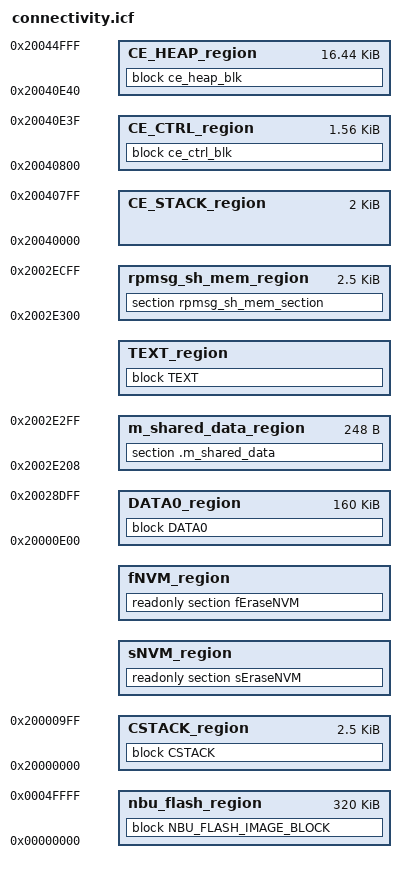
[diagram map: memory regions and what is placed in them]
/*
** ###################################################################
**     Processors:          MCXW70ACMFT
**                          MCXW70ACMMP
**
**     Compiler:            IAR ANSI C/C++ Compiler for ARM
**
**     Abstract:
**         Linker file for the IAR ANSI C/C++ Compiler for ARM for Connectivity Demo Applications
**
**     Copyright 2025-2026 NXP
**
**     SPDX-License-Identifier: BSD-3-Clause
**
**     http:                 www.nxp.com
**     mail:                 support@nxp.com
**
** ###################################################################
*/

/* Linker script for BLE or/and OpenThread applications
 * This is a generic layout with optional region that could be needed for BLE or OpenThread applications.
 * This Linker file can be used for BLE/OT combo applications. */

/*******************************************  core0/core1 common defines **********************************************/

/* flash */
define symbol m_flash_start = 0x0;
define symbol m_flash_size  = 0x180000;
define symbol m_flash_end   = m_flash_start + m_flash_size - 1;
define symbol m_sector_size = 0x2000;

/* FLW - the application flash region */
define symbol m_flw_start = 0x00800000;
define symbol m_flw_size  = 0x180000;
define symbol m_flw_end   = m_flw_start + m_flw_size - 1;

/* 320K reserved flash space for the Radio core at the beginning of the flash */
define symbol m_flash_radio_size    = 40 * m_sector_size;
define symbol m_flash_radio_start   = m_flash_start;
define symbol m_flash_radio_end     = m_flash_radio_start + m_flash_radio_size - 1;

/* RAM */
define symbol m_ram_size    = 0x10000; // all ram banks are 64K
define symbol m_ram0_start  = 0x20000000;
define symbol m_ram0_end    = m_ram0_start + m_ram_size -1;
define symbol m_ram1_start  = 0x20010000;
define symbol m_ram1_end    = m_ram1_start + m_ram_size - 1;
define symbol m_ram2_start  = 0x20020000;
define symbol m_ram2_end    = m_ram2_start + m_ram_size - 1;

/* ram3 is mapped to 0x04030000 as TCM-CODE but also remapped to 0x20030000 as TCM-SYSR (data)
 * For connectivity applications, this bank is reserved to the NBU core, core0 shall not use it */
define symbol m_ram3_start  = 0x20030000;
define symbol m_ram3_end    = m_ram3_start + m_ram_size - 1;

/* 8K shared ram between core0 and core1 - located at the end of the third ram bank */
define symbol m_shared_ram_size     = 0x2000;
define symbol m_shared_ram_end      = m_ram2_end;
define symbol m_shared_ram_start    = m_shared_ram_end - m_shared_ram_size + 1;

/* core0 and core1 RAM shared bank
 * core0 : 0x8E00 (35.5K)
 * core1 : 0x5200 (20.5K)
 * shared between both : 8k
*/
define symbol m_core1_shared_ram_end   = m_shared_ram_start - 1;
define symbol m_core1_shared_ram_size  = 0x5200;
define symbol m_core1_shared_ram_start = m_core1_shared_ram_end - m_core1_shared_ram_size + 1;

/* core0 reserved RAM (128K + 0x8E00 = 163.5K) */
define symbol m_core0_ram_start = m_ram0_start;
define symbol m_core0_ram_end   = m_core1_shared_ram_start - 1;

/* core1 reserved RAM (64k) */
define symbol m_core1_ram_start = m_ram3_start;
define symbol m_core1_ram_end   = m_ram3_end;

/* Shared memory placements
 * Do not change shall be aligned with nbu firmware image */

/* Section allowing to share debug info between core0 and core1 */
define exported symbol m_sqram_debug_start      = m_shared_ram_start;
define symbol m_sqram_debug_size                = 0x200;
define symbol m_sqram_debug_end                 = m_sqram_debug_start + m_sqram_debug_size - 1;

/* Section used to share platform/services (SFC, Lowpower) information */
define symbol framework_info_sh_mem_start       = m_sqram_debug_end + 1;
define symbol framework_info_sh_mem_size        = 0x100;
define symbol framework_info_sh_mem_end         = framework_info_sh_mem_start + framework_info_sh_mem_size - 1;
define exported symbol m_sfc_log_start          = framework_info_sh_mem_start;
define symbol m_sfc_log_size                    = 0x04;
define exported symbol m_lowpower_flag_start    = framework_info_sh_mem_start + m_sfc_log_size;
define symbol m_lowpower_flag_size              = 0x04;
define symbol m_lowpower_flag_end               = m_lowpower_flag_start + m_lowpower_flag_size - 1;
define symbol m_shared_data_start               = m_lowpower_flag_end + 1;
define symbol m_shared_data_size                = 0xF8;
define symbol m_shared_data_end                 = m_shared_data_start + m_shared_data_size - 1;
/* Make sure we don't overflow the framework_info_sh_mem */
check that m_shared_data_end <= framework_info_sh_mem_end;

define exported symbol rpmsg_sh_mem_start       = framework_info_sh_mem_end + 1;
define exported symbol rpmsg_sh_mem_size        = 0xA00;
define exported symbol rpmsg_sh_mem_end         = rpmsg_sh_mem_start + rpmsg_sh_mem_size - 1;

/* fill the remaining space with the logging buffer */
define exported symbol dbg_ext_logging_start    = rpmsg_sh_mem_end + 1;
define exported symbol dbg_ext_logging_size     = m_shared_ram_size - (dbg_ext_logging_start - m_shared_ram_start);
define exported symbol dbg_ext_logging_end      = dbg_ext_logging_start + dbg_ext_logging_size - 1;

/* Make sure we don't overflow the reserved shared memory region */
check that dbg_ext_logging_end <= m_shared_ram_end;

/*************************** FLASH LAYOUT ***********************************

                             0x001F_FFFF    m_flash_end
                    - - - +---------------+ - - - - - - - -
                          |               | m_fsl_prodInfo_end
                          |               |
                          | Product Info  | Enable with gUseProdInfoMainFlashMode_d=1
                          |               |
                          |               | m_fsl_prodInfo_start
                    - - - +---------------+ - - - - - - - -
                          |               | NV_STORAGE_END_ADDRESS
                          |  NV_STORAGE*  |
                          |               | Enable with gUseNVMLink_d=1
                          |               |
                          |               | NV_STORAGE_START_ADDRESS
                    - - - +---------------+ - - - - - - - -
                          |               | INT_STORAGE_END
                          |               |
                          |               |
                          |               |
                          | OTAP Internal | Enable with gUseInternalStorageLink_d=1
                          |      Storage* |
                          |               |
                          |               |
                          |               |
                          |               | INT_STORAGE_START
                    - - - +---------------+ - - - - - - - -
                          |               | m_text_end
                          |               |
                          |               |
                          |               |
                          | Application** |
                          |               |
                          |               |
                          |               |
                          |               | m_text_start
                    - - - +---------------+ - - - - - - - -
                          |   Interrupt   | m_interrupts_end
                          |    Vectors    |
                          |               | m_interrupts_start
                    - - - +---------------+ - - - - - - - -
                             0x0000_0000

        * - These sections are optional for certain applications
       ** - Application will occupy all the free space available
*****************************************************************************/

/* Symbols Flash checks */

if (!isdefinedsymbol(gUseNVMLink_d)) {
    define symbol gUseNVMLink_d = 0;
}

if (!isdefinedsymbol(gEraseNVMLink_d)) {
    define symbol gEraseNVMLink_d = 0;
}

if (!isdefinedsymbol(gUseInternalStorageLink_d)) {
    define symbol gUseInternalStorageLink_d = 0;
}

if (!isdefinedsymbol(gFlashNbuImage_d)) {
    define symbol gFlashNbuImage_d = 0;
}

/* By default, gFlashNbuLogging_d is not used. */
if (!isdefinedsymbol(gFlashNbuLogging_d)) {
    define symbol gFlashNbuLogging_d = 0;
}

if (!isdefinedsymbol(gUseProdInfoMainFlashMode_d)) {
    define symbol gUseProdInfoMainFlashMode_d = 0;
}

/* Symbols RAM checks */

/* Give SRAM room for ROM code to support warm boot from powerdown mode if this feature is supported and enabled */
if (!isdefinedsymbol(gLowpowerPowerDownEnable_d)) {
    define exported symbol gLowpowerPowerDownEnable_d = 0;
}
else {
    export symbol gLowpowerPowerDownEnable_d;
}

if (!isdefinedsymbol(gReserveCeRam_d)) {
    define exported symbol gReserveCeRam_d = 0;
}

/********************************************** FLASH **********************************************/

/* Flash defines */
define symbol m_vector_table_size                       = 0x400;   /* define is used for warmboot stack size too */

/* NVM and INT_STORAGE will use the physical flash address and not the FLW range
 * This adds some complexity because we have to translate between physical address and FLW address
 */

/* NVM storage */
if ( gUseNVMLink_d ) {
    if (isdefinedsymbol(gNVMSectorCountLink_d)) {
        define exported symbol NV_STORAGE_MAX_SECTORS   = gNVMSectorCountLink_d;
    }
    else {
        define exported symbol NV_STORAGE_MAX_SECTORS   = 4;
    }
}
else {
    define exported symbol NV_STORAGE_MAX_SECTORS       = 0;
}
define exported symbol NV_STORAGE_SECTOR_SIZE           = m_sector_size;
define exported symbol NV_STORAGE_END_ADDRESS           = m_flash_end; /* MUST use physical flash address and not FLW */
define exported symbol NV_STORAGE_SIZE                  = (NV_STORAGE_MAX_SECTORS * NV_STORAGE_SECTOR_SIZE);
define exported symbol NV_STORAGE_START_ADDRESS         = NV_STORAGE_END_ADDRESS - NV_STORAGE_SIZE + 1;

/* OTA */
define exported symbol INT_STORAGE_END                  = NV_STORAGE_START_ADDRESS - 1;
if (gUseInternalStorageLink_d) {
    /* The NBU firmware is located at the start of the flash so we have to compute the physical start address of the
     * application, meaning m_flash_start + m_flash_radio_size
     */
    define symbol m_app_flash_start                     = m_flash_start + m_flash_radio_size;
    define exported symbol INT_STORAGE_SIZE             = m_sector_size * ( ((INT_STORAGE_END + 1 - (m_app_flash_start))/2)/m_sector_size +1);
}
else {
    define exported symbol INT_STORAGE_SIZE             = 0;
}
define exported symbol INT_STORAGE_START                = INT_STORAGE_END - INT_STORAGE_SIZE + 1;
define exported symbol INT_STORAGE_SECTOR_SIZE          = m_sector_size;

/* This m_image_length is used to define the image length field in the vector table for boot ROM - it is mandatory.
 * We set it to the total available space for the application code minus the reserved areas.
 * We could simplify and use the whole FLW space but we wouldn't be able to detect if the application overflows
 * in the reserved areas since they are referring to the physical flash address instead of FLW.
 * This way, we are able to limit the size of the application code to the available space.
 */
define symbol m_reserved_size           = NV_STORAGE_END_ADDRESS - INT_STORAGE_START + 1;
define exported symbol m_image_length   = m_flw_size - m_flash_radio_size - m_reserved_size;

/* code is placed within FLW range */
define exported symbol m_text_start                     = m_flw_start;
define exported symbol m_text_end                       = m_flw_start + m_image_length - 1;
define exported symbol __VECTOR_TABLE                   = m_text_start;

/*************************** RAM LAYOUT ************************************/

/*
Default address values are indicated between brackets they can be overridden if necessary by linker flags


                    - - - +---------------+ - - - - - - - -
            (0x20044FFF)  |               | m_ce_heap_end
                          |               |
                          |               | Enable with gReserveCeRam_d=1
                          |               |
            (0x20040E40)  |               | m_ce_heap_start
                    - - - +---------------+ - - - - - - - -
            (0x20040E3F)  |               | m_ce_ctrl_end
                          |               |
                          |               | Enable with gReserveCeRam_d=1
                          |               |
            (0x20040800)  |               | m_ce_ctrl_start
                    - - - +---------------+ - - - - - - - -
            (0x200407FF)  |               | m_ce_stack_end
                          |               |
                          |               | Enable with gReserveCeRam_d=1
                          |               |
            (0x20040000)  |               | m_ce_stack_start
                   - - - +---------------+ - - - - - - - -
            (0x2003FFFF)  |               | m_core1_ram_end
                          |               |
                          |               |
            (0x20030000)  |               | m_core1_ram_start
                    - - - +---------------+ - - - - - - - -
            (0x2002FFFF)  |               | m_shared_ram_end
                          |               |
                          |               |
            (0x2002E000)  |               | m_shared_ram_start
                    - - - +---------------+ - - - - - - - -
            (0x2002DFFF)  |               | m_core1_shared_ram_end
                          |               |
                          |               |
            (0x20028E00)  |               | m_core1_shared_ram_start
                    - - - +---------------+ - - - - - - - -
              0x20028DFF  |     HEAP      | m_core0_ram_end \ m_data0_end \ __HEAP_end__
                          |               |
                          |               |
                          |...............| __HEAP_start__
                          |               |
                          .     Data0     .
                          .               .

            (0x20000E00)  |               | m_data0_start
                    - - - +---------------+ - - - - - - - -
                          |               | m_interrupts_ram_end
                          | vector table  |
            (0x20000A00)  |               | m_interrupts_ram_start
                    - - - +---------------+ - - - - - - - -
                          |               | m_cstack_end
                          |    Reserved   |
                          |               | m_cstack_start
                    - - - +---------------+ - - - - - - - -
              0x20000000  |               | m_core0_ram_start

**************************************************************************************************/

/********************************************** RAM **********************************************/

if (!isdefinedsymbol(__stack_size__))
{
    define symbol __stack_size__    = 0x0A00;
}

if (!isdefinedsymbol(__heap_size__))
{
    define symbol __heap_size__     = 0x0A00;
}

/* On A0 revisions of this chip, the CPU boot ROM does NOT correctly start the
 * application if the initial Main Stack Pointer (MSP) is located in SRAM1.
 * When the application’s SP is placed in SRAM1, the boot ROM refuses to jump
 * to the application entry point, resulting in a silent boot failure.
 *
 * Do NOT relocate the cstack region on A0 silicon.
 */
define exported symbol m_cstack_start                   = m_core0_ram_start;
define exported symbol m_cstack_end                     = m_cstack_start + __stack_size__ - 1;

/* Ram vector table */
define symbol m_interrupts_ram_start                    = m_cstack_end + 1;
define symbol m_ram_vector_table_size                   = m_vector_table_size;
define symbol m_interrupts_ram_end                      = m_interrupts_ram_start + m_ram_vector_table_size - 1;
define exported symbol __VECTOR_RAM                     = m_interrupts_ram_start;
define exported symbol __RAM_VECTOR_TABLE_SIZE          = m_ram_vector_table_size;

/* data0 region */
define symbol m_data0_start = m_interrupts_ram_end + 1;
define symbol m_data0_end   = m_core0_ram_end;

/* Data region Size for Compute Engine (CE) */
if (gReserveCeRam_d)
{
    define symbol m_ce_data_size                        = 0x1A000;
}
else
{
    define symbol m_ce_data_size                        = 0x0;
}

/* Heap region start and end address symbols used by usual memory allocator (malloc(), free())
   Not used by fsl_component_memory_manager_light component, __heap_size__ can be NULL */
define exported symbol __HEAP_start__                   = m_data0_end - __heap_size__;
define exported symbol __HEAP_end__                     = m_data0_end;

/* TODO: currently covering all the RAM to be safe */
define exported symbol firmware_ram_upper_limit         = m_core0_ram_end;
define exported symbol firmware_ram_lower_limit         = m_core0_ram_start;

/* Zephyr coredump LINKER_RAM region (DEBUG_COREDUMP_MEMORY_DUMP_LINKER_RAM,
 * the whole-RAM dump method). coredump_memory_regions.c brackets the RAM
 * portion of the dump between _image_ram_start and _image_ram_end. The Zephyr
 * build normally emits these; on the connectivity linker they are defined here
 * over the whole core0 RAM bank so the entire application RAM is dumped. */
define exported symbol _image_ram_start                 = m_core0_ram_start;
define exported symbol _image_ram_end                   = m_core0_ram_end;

/* The layout of the RAM and the region of each section have been reorganized in order
 * to optimize the RAM banks in retention. The heap at the top, we do not need to retain
 * banks upper of the last address used by the heap. */

/********************************************** Regions **********************************************/

/* shared memory regions */
define region rpmsg_sh_mem_region       = mem:[from rpmsg_sh_mem_start to rpmsg_sh_mem_end];
define region m_shared_data_region      = mem:[from m_shared_data_start to m_shared_data_end];

/* core0 memory regions */
define region TEXT_region               = mem:[from m_text_start to m_text_end];
define region DATA0_region              = mem:[from m_data0_start to m_data0_end];
define region CSTACK_region             = mem:[from m_cstack_start to m_cstack_end];

/* define blocks */
define block TEXT {
    first readonly section .intvec,
    readonly
};

/* Use DATA1_region for all connectivity code - DATA0_Region is 32K, can be used for customer specific code */
define block DATA0                                                  { readwrite, zi, last section .heap };
define block CSTACK    with alignment = 8, size = __stack_size__    { };

initialize by copy { readwrite, section .textrw };

if (isdefinedsymbol(__USE_DLIB_PERTHREAD))
{
  /* Required in a multi-threaded application */
  initialize by copy with packing = none { section __DLIB_PERTHREAD };
}

do not initialize  { section .noinit };
do not initialize  { section .heap };
do not initialize  { section .rpmsg_sh_mem_section};

/********************************************** PLACEMENT **********************************************/

/* shared memory placements */
place in rpmsg_sh_mem_region                    { section rpmsg_sh_mem_section };
place in m_shared_data_region                   { section .m_shared_data };

/* core0 memory placements */
place in TEXT_region                            { block TEXT };
place in DATA0_region                           { block DATA0 };
place in CSTACK_region                          { block CSTACK };

if (gUseNVMLink_d) {
    define symbol NV_VIRTUAL_PAGE_BOUND = NV_STORAGE_END_ADDRESS - (NV_STORAGE_MAX_SECTORS/2 * NV_STORAGE_SECTOR_SIZE);
    define region sNVM_region           = mem:[from  NV_VIRTUAL_PAGE_BOUND+1 to NV_STORAGE_END_ADDRESS];
    define region fNVM_region           = mem:[from  NV_STORAGE_START_ADDRESS to NV_VIRTUAL_PAGE_BOUND];
    if(gEraseNVMLink_d)
    {
        place in fNVM_region              {readonly section fEraseNVM };
        place in sNVM_region              {readonly section sEraseNVM };
    }
}

if (gUseInternalStorageLink_d) {
    define region InternalStorage       = mem:[from INT_STORAGE_START to INT_STORAGE_END];
}

if(gFlashNbuImage_d) {
    /* WARNING: the range here has to be consistent with symbol logging_start from nbu_flash_connectivity.icf */
    define exported symbol nbu_flash_image_start    = m_flash_radio_start;
    define exported symbol nbu_flash_image_end      = m_flash_radio_end;

    define region nbu_flash_region                  = mem:[from nbu_flash_image_start to nbu_flash_image_end];
    define block NBU_FLASH_IMAGE_BLOCK              { section  __nbu_flash };

    place in nbu_flash_region                       { block NBU_FLASH_IMAGE_BLOCK };
}

/********************************************** Localization Compute Engine (CE) Memory **********************************************/
if (gReserveCeRam_d)
{
/* The LCE code is placed in the core0 flash memory (13K)*/

/* memory used for the LCE stack (2K)*/
    define symbol m_ce_stack_start                = 0x20040000;
    define symbol m_ce_stack_size                 = 0x800;
    define symbol m_ce_stack_end                  = m_ce_stack_start + m_ce_stack_size -1;
/* memory used for Core0<-->LCE communication (1.5K)*/
    define symbol m_ce_ctrl_start                 = m_ce_stack_end + 1;
    define symbol m_ce_ctrl_size                  = 0x640;
    define symbol m_ce_ctrl_end                   = m_ce_ctrl_start + m_ce_ctrl_size -1;
/* memory used for LCE heap (16.4K)*/
    define symbol m_ce_heap_start                 = m_ce_ctrl_end + 1;
    define symbol m_ce_heap_size                  = 0x41C0;
    define symbol m_ce_heap_end                   = m_ce_heap_start + m_ce_heap_size -1;

    define region CE_CTRL_region            = mem:[from m_ce_ctrl_start to m_ce_ctrl_end];
    define region CE_HEAP_region            = mem:[from m_ce_heap_start to m_ce_heap_end];
    define region CE_STACK_region           = mem:[from m_ce_stack_start to m_ce_stack_end];

    define block ce_ctrl_blk        { section ceCtrl };
    define block ce_heap_blk        { section ceHeap };

/* There are two heap memory areas defined in the localization applications:
     - the main heap is accommodated at the end of DATA0_region
     - the heap used by LCE is accommodated in CE_HEAP_region   (14.4K) */

    place in CE_CTRL_region         { block ce_ctrl_blk };
    place in CE_HEAP_region         { block ce_heap_blk };

    define exported symbol __CE_MEM_HEAP_end__            = m_ce_heap_end;
}
